AUTOSAR XML (schema 4-2-2)
package /ServiceApplTemplate/SwComponentTypes
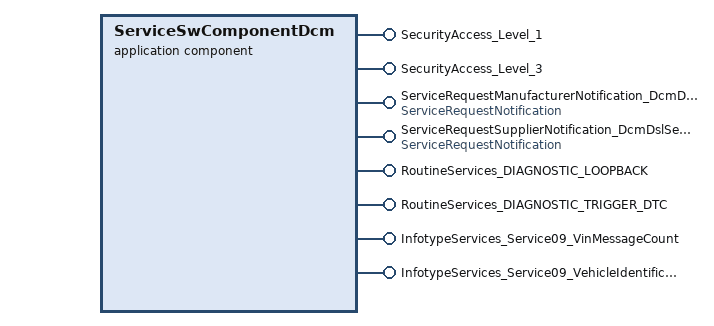
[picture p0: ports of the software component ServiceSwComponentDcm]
  application sw component type ServiceSwComponentDcm
    8 x provide port:
      SecurityAccess_Level_1: provided-interface=SecurityAccess_Level_1
      SecurityAccess_Level_3: provided-interface=SecurityAccess_Level_3
      ServiceRequestManufacturerNotification_DcmDslServiceRequestManufacturerNotification_0: provided-interface=ServiceRequestNotification
      ServiceRequestSupplierNotification_DcmDslServiceRequestSupplierNotification_0: provided-interface=ServiceRequestNotification
      RoutineServices_DIAGNOSTIC_LOOPBACK: provided-interface=RoutineServices_DIAGNOSTIC_LOOPBACK
      RoutineServices_DIAGNOSTIC_TRIGGER_DTC: provided-interface=RoutineServices_DIAGNOSTIC_TRIGGER_DTC
      InfotypeServices_Service09_VinMessageCount: provided-interface=InfotypeServices_Service09_VinMessageCount
      InfotypeServices_Service09_VehicleIdentificationNumber: provided-interface=InfotypeServices_Service09_VehicleIdentificationNumber
    behavior ServiceSwComponentDcm_IB: handle-termination-and-restart=NO-SUPPORT
      12 x operation invoked event:
        OIE_SecurityAccess_Level_1_84BB8A2232D0844AFF9F6DEBA909A8FE: start-on-event=Runnable_SecurityAccess_Level_1_84BB8A2232D0844AFF9F6DEBA909A8FE, operation=SecurityAccess_Level_1.GetSeed
        OIE_SecurityAccess_Level_1_8D467D058B9954F50FA4117D26D70750: start-on-event=Runnable_SecurityAccess_Level_1_8D467D058B9954F50FA4117D26D70750, operation=SecurityAccess_Level_1.CompareKey
        OIE_SecurityAccess_Level_3_02E23CEB188B01960F6123CEDAA46519: start-on-event=Runnable_SecurityAccess_Level_3_02E23CEB188B01960F6123CEDAA46519, operation=SecurityAccess_Level_3.GetSeed
        OIE_SecurityAccess_Level_3_BEFD23699B6D931568116397827F291C: start-on-event=Runnable_SecurityAccess_Level_3_BEFD23699B6D931568116397827F291C, operation=SecurityAccess_Level_3.CompareKey
        OIE_ServiceRequestManufacturerNotification_DcmDslServiceRequestManufacturerNotification_0_F96CE821EB615181C92F75B62FD8BB76: start-on-event=Runnable_ServiceRequestManufacturerNotification_DcmDslServiceRequestManufacturerNotification_0_F96CE821EB615181C92F75B62FD8BB76, operation=ServiceRequestManufacturerNotification_DcmDslServiceRequestManufacturerNotification_0.Indication
        OIE_ServiceRequestManufacturerNotification_DcmDslServiceRequestManufacturerNotification_0_FD82AF5E10E15A122DAD2F8A0D19766D: start-on-event=Runnable_ServiceRequestManufacturerNotification_DcmDslServiceRequestManufacturerNotification_0_FD82AF5E10E15A122DAD2F8A0D19766D, operation=ServiceRequestManufacturerNotification_DcmDslServiceRequestManufacturerNotification_0.Confirmation
        OIE_ServiceRequestSupplierNotification_DcmDslServiceRequestSupplierNotification_0_431FE507F5A42AFDBD075BD8121B2E12: start-on-event=Runnable_ServiceRequestSupplierNotification_DcmDslServiceRequestSupplierNotification_0_431FE507F5A42AFDBD075BD8121B2E12, operation=ServiceRequestSupplierNotification_DcmDslServiceRequestSupplierNotification_0.Indication
        OIE_ServiceRequestSupplierNotification_DcmDslServiceRequestSupplierNotification_0_35E0C438053C52243C98992C440E04EE: start-on-event=Runnable_ServiceRequestSupplierNotification_DcmDslServiceRequestSupplierNotification_0_35E0C438053C52243C98992C440E04EE, operation=ServiceRequestSupplierNotification_DcmDslServiceRequestSupplierNotification_0.Confirmation
        OIE_RoutineServices_DIAGNOSTIC_LOOPBACK_2ABDF5C8DB25E26D23A47D931863F3F4: start-on-event=Runnable_RoutineServices_DIAGNOSTIC_LOOPBACK_2ABDF5C8DB25E26D23A47D931863F3F4, operation=RoutineServices_DIAGNOSTIC_LOOPBACK.Start
        OIE_RoutineServices_DIAGNOSTIC_TRIGGER_DTC_A5663192471BAAA2C67D187118DC8330: start-on-event=Runnable_RoutineServices_DIAGNOSTIC_TRIGGER_DTC_A5663192471BAAA2C67D187118DC8330, operation=RoutineServices_DIAGNOSTIC_TRIGGER_DTC.Start
        OIE_InfotypeServices_Service09_VinMessageCount_1969977E6031A6FF8E94C48B46AEC7E7: start-on-event=Runnable_InfotypeServices_Service09_VinMessageCount_1969977E6031A6FF8E94C48B46AEC7E7, operation=InfotypeServices_Service09_VinMessageCount.GetInfotypeValueData
        OIE_InfotypeServices_Service09_VehicleIdentificationNumber_FCBCC756CD696C8B153A3B3C09098528: start-on-event=Runnable_InfotypeServices_Service09_VehicleIdentificationNumber_FCBCC756CD696C8B153A3B3C09098528, operation=InfotypeServices_Service09_VehicleIdentificationNumber.GetInfotypeValueData
      12 x runnable:
        Runnable_SecurityAccess_Level_1_84BB8A2232D0844AFF9F6DEBA909A8FE: symbol=ServiceSwComponentDcm_SecurityAccess_Level_1_GetSeed
        Runnable_SecurityAccess_Level_1_8D467D058B9954F50FA4117D26D70750: symbol=ServiceSwComponentDcm_SecurityAccess_Level_1_CompareKey
        Runnable_SecurityAccess_Level_3_02E23CEB188B01960F6123CEDAA46519: symbol=ServiceSwComponentDcm_SecurityAccess_Level_3_GetSeed
        Runnable_SecurityAccess_Level_3_BEFD23699B6D931568116397827F291C: symbol=ServiceSwComponentDcm_SecurityAccess_Level_3_CompareKey
        Runnable_ServiceRequestManufacturerNotification_DcmDslServiceRequestManufacturerNotification_0_F96CE821EB615181C92F75B62FD8BB76: symbol=ServiceSwComponentDcm_ServiceRequestManufacturerNotification_DcmDslServiceRequestManufacturerNotification_0_Indication
        Runnable_ServiceRequestManufacturerNotification_DcmDslServiceRequestManufacturerNotification_0_FD82AF5E10E15A122DAD2F8A0D19766D: symbol=ServiceSwComponentDcm_ServiceRequestManufacturerNotification_DcmDslServiceRequestManufacturerNotification_0_Confirmation
        Runnable_ServiceRequestSupplierNotification_DcmDslServiceRequestSupplierNotification_0_431FE507F5A42AFDBD075BD8121B2E12: symbol=ServiceSwComponentDcm_ServiceRequestSupplierNotification_DcmDslServiceRequestSupplierNotification_0_Indication
        Runnable_ServiceRequestSupplierNotification_DcmDslServiceRequestSupplierNotification_0_35E0C438053C52243C98992C440E04EE: symbol=ServiceSwComponentDcm_ServiceRequestSupplierNotification_DcmDslServiceRequestSupplierNotification_0_Confirmation
        Runnable_RoutineServices_DIAGNOSTIC_LOOPBACK_2ABDF5C8DB25E26D23A47D931863F3F4: symbol=ServiceSwComponentDcm_RoutineServices_DIAGNOSTIC_LOOPBACK_Start
        Runnable_RoutineServices_DIAGNOSTIC_TRIGGER_DTC_A5663192471BAAA2C67D187118DC8330: symbol=ServiceSwComponentDcm_RoutineServices_DIAGNOSTIC_TRIGGER_DTC_Start
        Runnable_InfotypeServices_Service09_VinMessageCount_1969977E6031A6FF8E94C48B46AEC7E7: symbol=ServiceSwComponentDcm_InfotypeServices_Service09_VinMessageCount_GetInfotypeValueData
        Runnable_InfotypeServices_Service09_VehicleIdentificationNumber_FCBCC756CD696C8B153A3B3C09098528: symbol=ServiceSwComponentDcm_InfotypeServices_Service09_VehicleIdentificationNumber_GetInfotypeValueData
  swc implementation ServiceSwComponentDcm_Impl: programming-language=C, sw-version=1.0.0, vendor-id=1, behavior=ServiceSwComponentDcm_IB
    code-descriptors:
      code CodeDescriptor: artifact-descriptors=autosar-engineering-object={short-label=EngObject, category=SWSRC}
    resource consumption ResourceConsumption
      memory section Code: sw-addrmethod=CODE, symbol=CODE
package /DemoApplication/SwComponentTypes
  composition sw component type TopLevelComposition
    component ServiceSwComponentDcm: type=ServiceSwComponentDcm
    connect ServiceSwComponentDcm.SecurityAccess_Level_1 -> Dcm_Prototype.SecurityAccess_Level_1
    connect ServiceSwComponentDcm.SecurityAccess_Level_3 -> Dcm_Prototype.SecurityAccess_Level_3
    connect ServiceSwComponentDcm.ServiceRequestManufacturerNotification_DcmDslServiceRequestManufacturerNotification_0 -> Dcm_Prototype.ServiceRequestManufacturerNotification_DcmDslServiceRequestManufacturerNotification_0
    connect ServiceSwComponentDcm.ServiceRequestSupplierNotification_DcmDslServiceRequestSupplierNotification_0 -> Dcm_Prototype.ServiceRequestSupplierNotification_DcmDslServiceRequestSupplierNotification_0
    connect ServiceSwComponentDcm.RoutineServices_DIAGNOSTIC_LOOPBACK -> Dcm_Prototype.RoutineServices_DIAGNOSTIC_LOOPBACK
    connect ServiceSwComponentDcm.RoutineServices_DIAGNOSTIC_TRIGGER_DTC -> Dcm_Prototype.RoutineServices_DIAGNOSTIC_TRIGGER_DTC
    connect ServiceSwComponentDcm.InfotypeServices_Service09_VinMessageCount -> Dcm_Prototype.InfotypeServices_Service09_VinMessageCount
    connect ServiceSwComponentDcm.InfotypeServices_Service09_VehicleIdentificationNumber -> Dcm_Prototype.InfotypeServices_Service09_VehicleIdentificationNumber
package /CanSystem
  system CanSystem
    system mapping ServiceSwComponentDcmSystemMappings
      sw-mappings:
        swc to ecu mapping ServiceSwComponentDcmSwcToEcuMapping: component=TopLevelComposition.ServiceSwComponentDcm, ecu-instance=EcuTestNode
